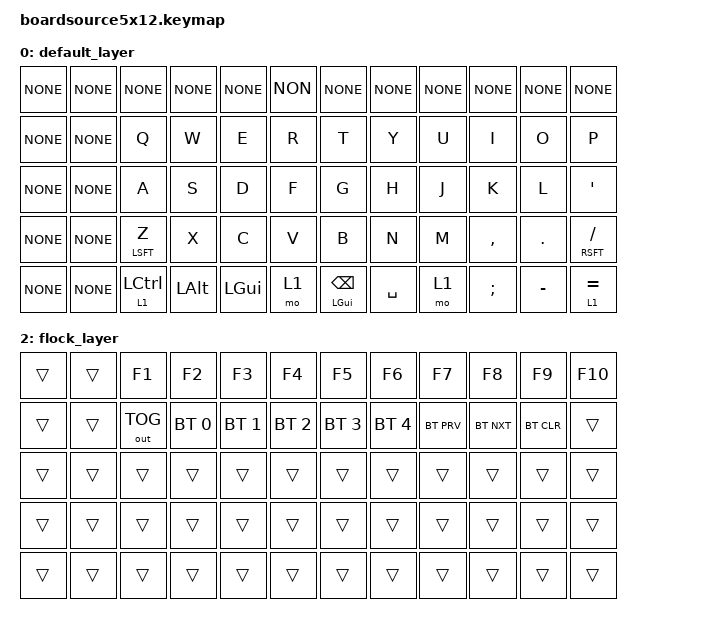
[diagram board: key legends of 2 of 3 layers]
/*
 * Copyright (c) 2021 The ZMK Contributors
 *
 * SPDX-License-Identifier: MIT
 */
 
#include <behaviors.dtsi>
#include <dt-bindings/zmk/keys.h>
#include <dt-bindings/zmk/bt.h>
#include <dt-bindings/zmk/outputs.h>

&mt {
    retro-tap;
};

/ {
	keymap {
		compatible = "zmk,keymap";

		default_layer {
			// ------------------------------------------------------------------------------------------
			// |  ESC  |  1   |  2   |  3   |  4   |  5   |   6   |  7    |  8   |  9   |   0   | BSPC  |
			// |  TAB  |  Q   |  W   |  E   |  R   |  T   |   Y   |  U    |  I   |  O   |   P   |  \    |
			// | SHIFT |  A   |  S   |  D   |  F   |  G   |   H   |  J    |  K   |  L   |   ;   |  '    |
			// | CTRL  |  Z   |  X   |  C   |  V   |  B   |   N   |  M    |  ,   |  .   |   /   | ENTER |
			// |ADJUST | LCTL | LALT | LGUI | LOWR | SPACE| SPACE |  RAIS | LARW | DARW | UARW  | RARW  |


			bindings = <
				&kp NONE	&kp NONE	&kp NONE	&kp NONE	&kp NONE	&kp NON		&kp NONE		&kp NONE	&kp NONE	&kp NONE	&kp NONE	&kp NONE
				&kp NONE	&kp NONE	&kp Q		&kp W		&kp E		&kp R		&kp T			&kp Y		&kp U		&kp I		&kp O		&kp P       
				&kp NONE	&kp NONE	&kp A		&kp S		&kp D		&kp F		&kp G			&kp H		&kp J		&kp K		&kp L		&kp SQT    
				&kp NONE	&kp NONE	&mt LSFT Z	&kp X		&kp C		&kp V		&kp B			&kp N		&kp M		&kp COMMA	&kp DOT		&mt RSFT FSLH    
				&kp NONE	&kp NONE	&lt 1 LCTRL	&kp LALT	&kp LGUI	&mo 1		&mt LGUI BKSP	&kp SPACE	&mo 1		&kp SEMI	&kp MINUS	&lt 1 EQL
			>;
		};

		lower_layer {
			// -------------------------------------------------------------------------------------------
			// |  ESC  |  F2  |  F3  |  F4  |  F5  |  F6  |   F7  |  F8   |  F9  | F10  |  F11  |  F12  |
			// |   ~   |  !   |  @   |  #   |  $   |  %   |   ^   |	&   |  *   |  (   |   )   |  DEL  |
			// |       |  F1  |  F2  |  F3  |  F4  |  F5  |   F6  |   _   |  +   |  {   |   }   |   |   |
			// |       |  F7  |  F8  |  F9  |  F10 |  F11 |   F12 | LS(#) |LS(|) |      |       |       |
			// |       |      |      |      |      |      |       |       | NEXT | Vol- | Vol+ | PLAY   |
			bindings = <
				&trans	&trans	&kp LA(BSPC)	&kp  LA(LEFT)	&kp UP		&kp RET		&kp LA(RIGHT) 	&trans	&trans	&trans	&trans	&kp PIPE	
				&trans	&trans	&kp	HOME 		&kp LEFT		&kp DOWN	&kp RIGHT	&kp END 		&trans	&trans	&trans	&trans	&kp SEMI	
				&trans	&trans	&mt LSFT N1		&kp N2			&kp N3		&kp N4		&kp N5			&kp N6	&kp N7	&kp N8	&kp N9 	&mt RSFT  N10
				&trans	&trans	&trans			&trans			&trans		&trans		&trans			&trans 	&trans	&trans	&trans	&trans	
			>;		};

		flock_layer {
			bindings = <
				&trans	&trans	&kp F1			&kp F2			&kp F3			&kp F4			&kp F5			&kp F6			&kp F7 		&kp F8 		&kp F9 		&kp F10	
				&trans	&trans	&out OUT_TOG	&bt BT_SEL 0	&bt BT_SEL 1	&bt BT_SEL 2	&bt BT_SEL 3	&bt BT_SEL 4	&bt BT_PRV	&bt BT_NXT	&bt BT_CLR	&trans	 
				&trans	&trans	&trans			&trans			&trans			&trans			&trans	 		&trans		&trans		&trans		&trans	&trans	
				&trans	&trans	&trans			&trans			&trans			&trans			&trans	 		&trans		&trans		&trans		&trans	&trans	
				&trans	&trans	&trans			&trans			&trans			&trans			&trans	 		&trans		&trans		&trans		&trans	&trans	
			>;
		};
	};
	combos {
        compatible = "zmk,combos";
        combo_esc {
            timeout-ms = <50>;
            key-positions = <15 16>;
            bindings = <&kp ESC>;
        };
		combo_tab {
            timeout-ms = <50>;
            key-positions = <15 16>;
            bindings = <&kp ESC>;
        };
		combo_ {
            timeout-ms = <50>;
            key-positions = <15 16>;
            bindings = <&kp ESC>;
        };
		combo_enter {
            timeout-ms = <50>;
            key-positions = <35 36>;
            bindings = <&kp ENTER>;
        };
		combo_delwd {
			timeout-ms = <50>;
			key-positions = <29 30>;
			bindings = <&kp LA(BSPC)>;
		};
    };
};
